# CY8C5868AXI_LP035 register map
File version: 0.1
Registers are 8-bit, read-write, no defined reset value unless marked. A register's access mark holds for its fields unless they carry their own. Offsets are from the block's base; [hi:lo] are bit positions; 'fields as' and 'values as' point back to an identical list.

## UART_1 — UART
Base 0x00000000
0x4000652B RX_UART_1_RX_ADDRESS1 — RX Address1 Register
0x4000653B RX_UART_1_RX_ADDRESS2 — RX Address2 Register
0x40006548 TX_UART_1_TX_DATA — TX Data Register
0x4000654B RX_UART_1_RX_DATA — RX Data Register
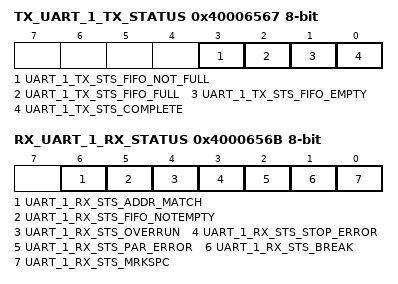
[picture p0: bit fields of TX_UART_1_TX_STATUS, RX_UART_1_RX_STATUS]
0x40006567 TX_UART_1_TX_STATUS — TX status register
  [3] UART_1_TX_STS_FIFO_NOT_FULL ro, [2] UART_1_TX_STS_FIFO_FULL ro, [1] UART_1_TX_STS_FIFO_EMPTY ro, [0] UART_1_TX_STS_COMPLETE ro
0x4000656B RX_UART_1_RX_STATUS — RX status register
  [6] UART_1_RX_STS_ADDR_MATCH ro, [5] UART_1_RX_STS_FIFO_NOTEMPTY ro, [4] UART_1_RX_STS_OVERRUN ro, [3] UART_1_RX_STS_STOP_ERROR ro, [2] UART_1_RX_STS_PAR_ERROR ro, [1] UART_1_RX_STS_BREAK ro, [0] UART_1_RX_STS_MRKSPC ro

## High_Frequency_PWM_1
Base 0x00000000
0x40006428 High_Frequency_PWM_1_COMPARE_Reg 16-bit — UDB.D0 - Assigned Compare Value
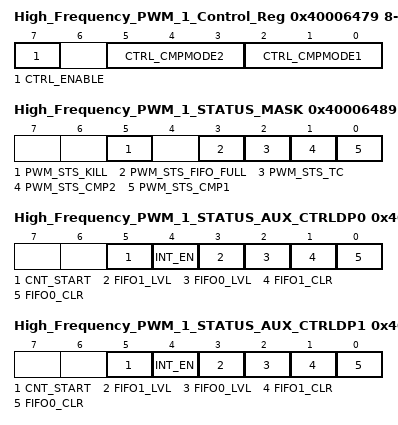
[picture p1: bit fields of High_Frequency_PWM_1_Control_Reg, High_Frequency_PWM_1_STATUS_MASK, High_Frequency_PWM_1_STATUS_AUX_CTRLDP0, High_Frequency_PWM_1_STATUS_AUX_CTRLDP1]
0x40006479 High_Frequency_PWM_1_Control_Reg — UDB Control Register - Assigned Control Register Value
  [7] CTRL_ENABLE — Enable the PWM
  [5:3] CTRL_CMPMODE2 — Compare mode 2
  [2:0] CTRL_CMPMODE1 — Compare mode 1
0x40006489 High_Frequency_PWM_1_STATUS_MASK — UDB Status bits Interrupt Mask Enable Register
  [5] PWM_STS_KILL ro — Enables the Interrupt on Kill
  [3] PWM_STS_FIFO_FULL ro — FIFO Full Status Mask
  [2] PWM_STS_TC ro — Enables the Interrupt on Terminal Count
  [1] PWM_STS_CMP2 ro — Enables the Interrupt on Compare 2
  [0] PWM_STS_CMP1 ro — Enables the Interrupt on Compare 1
0x40006498 High_Frequency_PWM_1_STATUS_AUX_CTRLDP0 — UDB Auxilliary Control Register
  [5] CNT_START — FIFO0 clear
    0=E_CNT_START0 (Disable counter); 1=E_CNT_START1 (Enable counter)
  [4] INT_EN
    0=E_INT_EN0 (Interrupt disabled); 1=E_INT_EN1 (Interrupt enabled)
  [3] FIFO1_LVL — FIFO level
    0=E_FIFO_LVL_0 (FIFO LVL: input mode: FIFO not full; output mode: FIFO not empty); 1=E_FIFO_LVL_1 (FIFO LVL: input mode: FIFO at least 1/2 empty; output mode: FIFO at least 1/2 full)
  [2] FIFO0_LVL — FIFO level
    values as FIFO1_LVL
  [1] FIFO1_CLR — FIFO1 clear
    0=E_FIFO_CLR_0 (Normal FIFO operation); 1=E_FIFO_CLR_1 (Clear FIFO state)
  [0] FIFO0_CLR — FIFO0 clear
    values as FIFO1_CLR
0x40006499 High_Frequency_PWM_1_STATUS_AUX_CTRLDP1 — UDB Auxilliary Control Register
  fields as High_Frequency_PWM_1_STATUS_AUX_CTRLDP0

## High_Frequency_PWM_0
Base 0x00000000
0x40006526 High_Frequency_PWM_0_COMPARE_Reg 16-bit — UDB.D0 - Assigned Compare Value
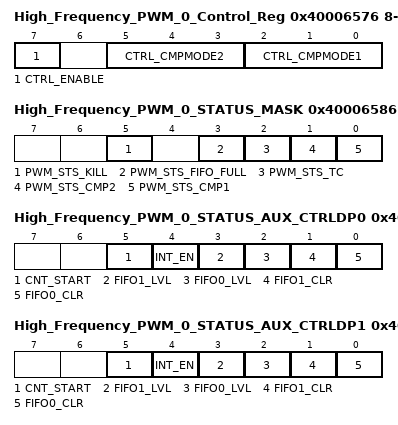
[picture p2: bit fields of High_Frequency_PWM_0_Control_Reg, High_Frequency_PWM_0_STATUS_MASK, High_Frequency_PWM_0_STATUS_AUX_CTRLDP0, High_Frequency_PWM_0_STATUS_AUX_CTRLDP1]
0x40006576 High_Frequency_PWM_0_Control_Reg — UDB Control Register - Assigned Control Register Value
  [7] CTRL_ENABLE — Enable the PWM
  [5:3] CTRL_CMPMODE2 — Compare mode 2
  [2:0] CTRL_CMPMODE1 — Compare mode 1
0x40006586 High_Frequency_PWM_0_STATUS_MASK — UDB Status bits Interrupt Mask Enable Register
  [5] PWM_STS_KILL ro — Enables the Interrupt on Kill
  [3] PWM_STS_FIFO_FULL ro — FIFO Full Status Mask
  [2] PWM_STS_TC ro — Enables the Interrupt on Terminal Count
  [1] PWM_STS_CMP2 ro — Enables the Interrupt on Compare 2
  [0] PWM_STS_CMP1 ro — Enables the Interrupt on Compare 1
0x40006596 High_Frequency_PWM_0_STATUS_AUX_CTRLDP0 — UDB Auxilliary Control Register
  [5] CNT_START — FIFO0 clear
    0=E_CNT_START0 (Disable counter); 1=E_CNT_START1 (Enable counter)
  [4] INT_EN
    0=E_INT_EN0 (Interrupt disabled); 1=E_INT_EN1 (Interrupt enabled)
  [3] FIFO1_LVL — FIFO level
    0=E_FIFO_LVL_0 (FIFO LVL: input mode: FIFO not full; output mode: FIFO not empty); 1=E_FIFO_LVL_1 (FIFO LVL: input mode: FIFO at least 1/2 empty; output mode: FIFO at least 1/2 full)
  [2] FIFO0_LVL — FIFO level
    values as FIFO1_LVL
  [1] FIFO1_CLR — FIFO1 clear
    0=E_FIFO_CLR_0 (Normal FIFO operation); 1=E_FIFO_CLR_1 (Clear FIFO state)
  [0] FIFO0_CLR — FIFO0 clear
    values as FIFO1_CLR
0x40006597 High_Frequency_PWM_0_STATUS_AUX_CTRLDP1 — UDB Auxilliary Control Register
  fields as High_Frequency_PWM_0_STATUS_AUX_CTRLDP0
